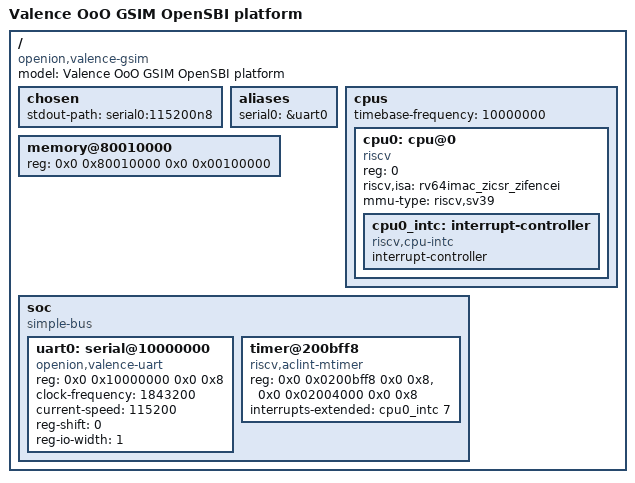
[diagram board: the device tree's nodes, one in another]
/dts-v1/;

/ {
    #address-cells = <2>;
    #size-cells = <2>;
    compatible = "openion,valence-gsim";
    model = "Valence OoO GSIM OpenSBI platform";

    chosen {
        stdout-path = "serial0:115200n8";
    };

    aliases {
        serial0 = &uart0;
    };

    cpus {
        #address-cells = <1>;
        #size-cells = <0>;
        timebase-frequency = <10000000>;

        cpu0: cpu@0 {
            device_type = "cpu";
            reg = <0>;
            compatible = "riscv";
            riscv,isa = "rv64imac_zicsr_zifencei";
            mmu-type = "riscv,sv39";
            status = "okay";

            cpu0_intc: interrupt-controller {
                compatible = "riscv,cpu-intc";
                interrupt-controller;
                #interrupt-cells = <1>;
            };
        };
    };

    memory@80010000 {
        device_type = "memory";
        reg = <0x0 0x80010000 0x0 0x00100000>;
    };

    soc {
        compatible = "simple-bus";
        #address-cells = <2>;
        #size-cells = <2>;
        ranges;

        uart0: serial@10000000 {
            compatible = "openion,valence-uart", "ns16550a";
            reg = <0x0 0x10000000 0x0 0x8>;
            clock-frequency = <1843200>;
            current-speed = <115200>;
            reg-shift = <0>;
            reg-io-width = <1>;
            status = "okay";
        };

        timer@200bff8 {
            compatible = "riscv,aclint-mtimer";
            reg = <0x0 0x0200bff8 0x0 0x8>,
                  <0x0 0x02004000 0x0 0x8>;
            interrupts-extended = <&cpu0_intc 7>;
        };
    };
};
